# STM32H5xx register map
File version: 0.3
CPU: CM33 r0p0, little endian, MPU, FPU, 4 interrupt priority bits
Registers are 32-bit, read-write, reset 0x0 unless marked. A register's access mark holds for its fields unless they carry their own. Offsets are from the block's base; [hi:lo] are bit positions; {n}, {i} and the like mark numbered series.

## GPIOI — General-purpose I/Os
Base 0x42022000
Same registers: SEC_GPIOI 0x52022000
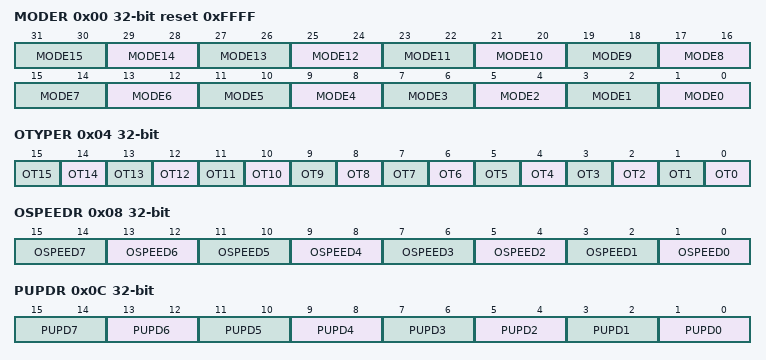
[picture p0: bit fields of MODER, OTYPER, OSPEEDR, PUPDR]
0x00 MODER reset 0xFFFF — GPIO port mode register
  [2n+1:2n] MODE{n} (n=0..15) — Port x configuration bits (y = 0..15)
0x04 OTYPER — GPIO port output type register
  [n] OT{n} (n=0..15) — Port x configuration bits (y = 0..15)
0x08 OSPEEDR — GPIO port output speed register
  [2n+1:2n] OSPEED{n} (n=0..7) — Port x configuration bits (y =7 .. 0)
0x0C PUPDR — GPIO port pull-up/pull-down register
  [2n+1:2n] PUPD{n} (n=0..7) — Port x configuration bits (y =7 .. 0)
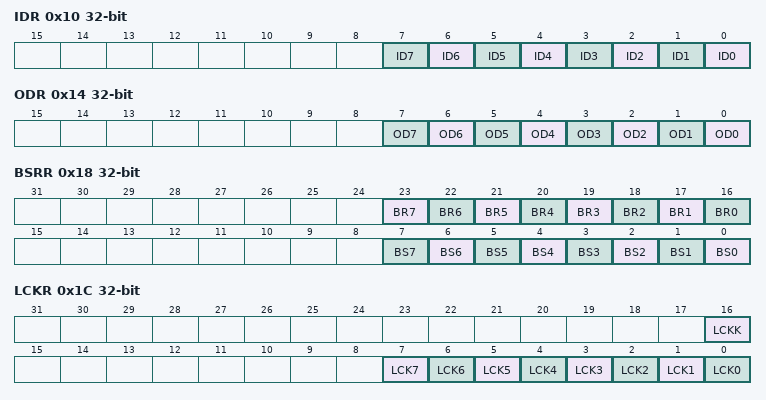
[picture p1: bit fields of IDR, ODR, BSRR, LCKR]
0x10 IDR ro — GPIO port input data register
  [n] ID{n} (n=0..7) — Port input data (y = 0..7)
0x14 ODR — GPIO port output data register
  [n] OD{n} (n=0..7) — Port output data (y = 0..7)
0x18 BSRR wo — GPIO port bit set/reset register
  [n+16] BR{n} (n=1..7) — Port x reset bit y (y = 0..7)
  [16] BR0 — Port x set bit y (y= 0..7)
  [n] BS{n} (n=0..7) — Port x set bit y (y= 0..7)
0x1C LCKR — GPIO port configuration lock register
  [16] LCKK — Lock key
  [n] LCK{n} (n=0..7) — Port x lock bit y (y= 0..15)
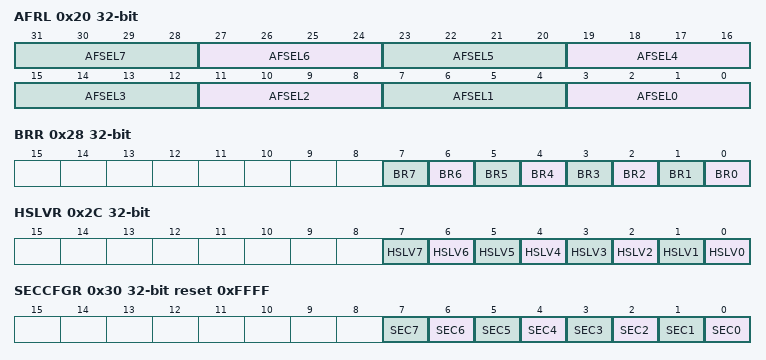
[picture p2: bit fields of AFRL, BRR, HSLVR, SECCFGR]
0x20 AFRL — GPIO alternate function low register
  [4n+3:4n] AFSEL{n} (n=0..7) — Alternate function selection for port x bit y (y = 0..7)
0x28 BRR wo — GPIO port bit reset register
  [n] BR{n} (n=0..7) — Port x reset IO pin y
0x2C HSLVR — GPIO high-speed low-voltage register
  [n] HSLV{n} (n=0..7) — Port x high-speed low-voltage configuration (y= 7 to 0)
0x30 SECCFGR wo reset 0xFFFF — GPIO secure configuration register
  [n] SEC{n} (n=0..7) — I/O pin of Port x secure bit enable

## PKA — Private key accelerator
Base 0x420C2000
Same registers: SEC_PKA 0x520C2000
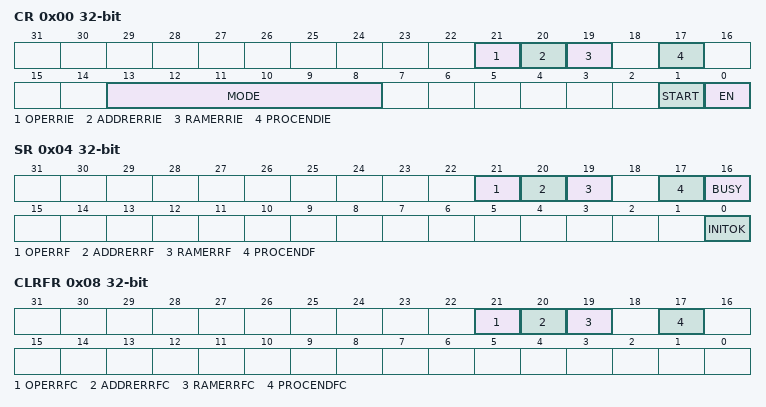
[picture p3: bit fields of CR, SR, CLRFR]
0x00 CR — Control register
  [21] OPERRIE — Operation error interrupt enable
  [20] ADDRERRIE — Address error interrupt enable
  [19] RAMERRIE — RAM error interrupt enable
  [17] PROCENDIE — End of operation interrupt enable
  [13:8] MODE — PKA Operation Mode
  [1] START — Start the operation
  [0] EN — Peripheral Enable
0x04 SR ro — PKA status register
  [21] OPERRF
  [20] ADDRERRF
  [19] RAMERRF
  [17] PROCENDF — PKA End of Operation flag
  [16] BUSY — PKA operation is in progress
  [0] INITOK
0x08 CLRFR wo — PKA clear flag register
  [21] OPERRFC
  [20] ADDRERRFC
  [19] RAMERRFC
  [17] PROCENDFC — Clear PKA End of Operation flag

## IWDG — Independent watchdog
Base 0x40003000
Same registers: SEC_IWDG 0x50003000
0x00 KR wo — Key register
  [15:0] KEY — Key value (write only, read 0x0000)
0x04 PR — Prescaler register
  [3:0] PR — Prescaler divider
0x08 RLR reset 0xFFF — Reload register
  [11:0] RL — Watchdog counter reload value
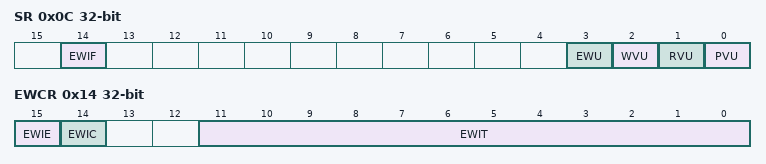
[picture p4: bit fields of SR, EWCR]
0x0C SR ro — Status register
  [14] EWIF — Watchdog Early interrupt flag
  [3] EWU — Watchdog interrupt comparator value update
  [2] WVU — Watchdog counter window value update
  [1] RVU — Watchdog counter reload value update
  [0] PVU — Watchdog prescaler value update
0x10 WINR reset 0xFFF — Window register
  [11:0] WIN — Watchdog counter window value
0x14 EWCR — IWDG early wakeup interrupt register
  [15] EWIE — Watchdog early interrupt enable
  [14] EWIC — Watchdog early interrupt acknowledge
  [11:0] EWIT — Watchdog counter window value

## VREFBUF — Voltage reference buffer
Base 0x46007400
Same registers: SEC_VREFBUF 0x56007400
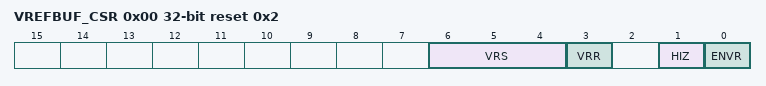
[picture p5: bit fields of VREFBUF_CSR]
0x00 VREFBUF_CSR access per field reset 0x2 — VREFBUF control and status register
  [6:4] VRS rw, [3] VRR ro, [1] HIZ rw, [0] ENVR rw
0x04 VREFBUF_CCR — VREFBUF calibration control register
  [5:0] TRIM

## WWDG — System window watchdog
Base 0x40002C00
Same registers: SEC_WWDG 0x50002C00
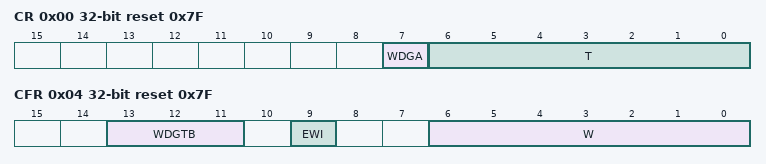
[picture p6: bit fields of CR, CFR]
0x00 CR reset 0x7F — Control register
  [7] WDGA — Activation bit
  [6:0] T — 7-bit counter (MSB to LSB)
0x04 CFR reset 0x7F — Configuration register
  [13:11] WDGTB — Timer base
  [9] EWI — Early wakeup interrupt
  [6:0] W — 7-bit window value
0x08 SR — Status register
  [0] EWIF — Early wakeup interrupt flag
